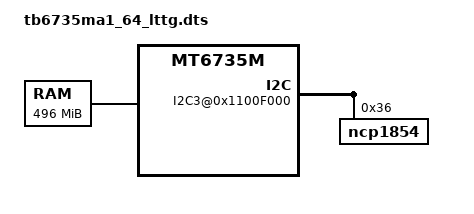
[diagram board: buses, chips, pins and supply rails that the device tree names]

/dts-v1/;

/include/ "mt6735m.dtsi"

/ {
  memory@00000000 {
		device_type = "memory";
		reg = <0 0x40000000 0 0x1F000000>;
	};
reserved-memory {
		#address-cells = <2>;
		#size-cells = <2>;
		ranges;

		reserve-memory-ccci_md1 {
			compatible = "reserve-memory-ccci_md1";
			no-map;
			size = <0 0x3010000>; // md_size+smem_size
			alignment = <0 0x2000000>;
			alloc-ranges = <0 0x40000000 0 0xC0000000>;
		};
	};
	bus {
		compatible = "simple-bus";
		#address-cells = <1>;
		#size-cells = <1>;
		ranges = <0 0 0 0xffffffff>;

		I2C3@0x1100F000 {
			ncp1854@36 {
				compatible = "ncp1854";
				reg = <0x36>;
			};
		};

		MTKFB@5e200000 {
			compatible = "mediatek,MTKFB";
			reg = <0x7F000000 0x1000000>;
		};

  };
};
